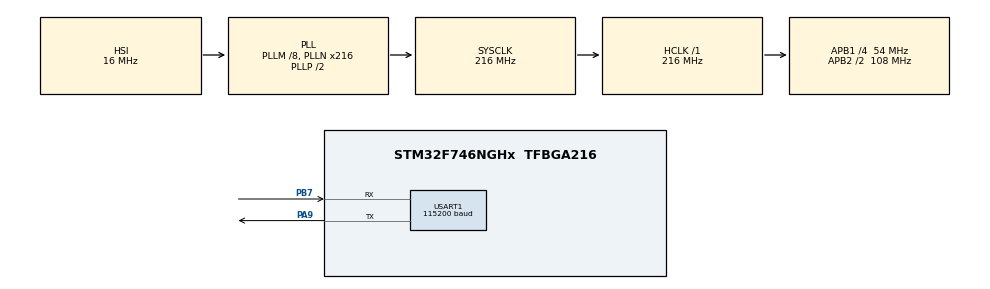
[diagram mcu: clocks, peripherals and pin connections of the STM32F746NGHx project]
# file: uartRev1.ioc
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CORTEX_M7.ART_ACCLERATOR_ENABLE=1
CORTEX_M7.CPU_DCache=Enabled
CORTEX_M7.CPU_ICache=Enabled
CORTEX_M7.PREFETCH_ENABLE=1
Mcu.Family=STM32F7
Mcu.Name=STM32F746NGHx
Mcu.Package=TFBGA216
NVIC.PriorityGroup=NVIC_PRIORITYGROUP_4
NVIC.RCC_IRQn=true\:0\:0\:false\:false\:true\:true\:false
PA13.Mode=Serial_Wire
PA13.Signal=SYS_JTMS-SWDIO
PA14.Mode=Serial_Wire
PA14.Signal=SYS_JTCK-SWCLK
PA9.Mode=Asynchronous
PA9.Signal=USART1_TX
PB7.Mode=Asynchronous
PB7.Signal=USART1_RX
ProjectManager.HeapSize=0x200
ProjectManager.StackSize=0x400
ProjectManager.TargetToolchain=MDK-ARM V5.32
RCC.AHBFreq_Value=216000000
RCC.APB1CLKDivider=RCC_HCLK_DIV4
RCC.APB1Freq_Value=54000000
RCC.APB1TimFreq_Value=108000000
RCC.APB2CLKDivider=RCC_HCLK_DIV2
RCC.APB2Freq_Value=108000000
RCC.APB2TimFreq_Value=216000000
RCC.CortexFreq_Value=216000000
RCC.HCLKFreq_Value=216000000
RCC.HSE_VALUE=25000000
RCC.HSI_VALUE=16000000
RCC.LSE_VALUE=32768
RCC.PLLM=8
RCC.PLLN=216
RCC.PLLSourceVirtual=RCC_PLLSOURCE_HSI
RCC.SYSCLKFreq_VALUE=216000000
RCC.SYSCLKSource=RCC_SYSCLKSOURCE_PLLCLK
RCC.USBFreq_Value=216000000
RCC.VCOOutputFreq_Value=432000000
USART1.BaudRate=115200
USART1.VirtualMode-Asynchronous=VM_ASYNC
board=STM32F746G-DISCO

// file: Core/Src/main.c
/* USER CODE BEGIN Header */
/**
  ******************************************************************************
  * @file           : main.c
  * @brief          : Main program body
  ******************************************************************************
  * @attention
  *
  * <h2><center>&copy; Copyright (c) 2021 STMicroelectronics.
  * All rights reserved.</center></h2>
  *
  * This software component is licensed by ST under BSD 3-Clause license,
  * the "License"; You may not use this file except in compliance with the
  * License. You may obtain a copy of the License at:
  *                        opensource.org/licenses/BSD-3-Clause
  *
  ******************************************************************************
  */
/* USER CODE END Header */
#include "main.h"

/* USER CODE BEGIN Includes */
#include "stdio.h"
#include "arm_nnfunctions.h"
#include "model.h"
#include "utils.h"
#include "inputs.h"

/* USER CODE END Includes */

/* USER CODE BEGIN PD */
int stdout_putchar (int ch);
/* USER CODE END PD */

UART_HandleTypeDef huart1;

void SystemClock_Config(void);
static void MX_GPIO_Init(void);
static void MX_USART1_UART_Init(void);

int main(void)
{

  /* Enable I-Cache---------------------------------------------------------*/
  SCB_EnableICache();

  /* Enable D-Cache---------------------------------------------------------*/
  SCB_EnableDCache();

  /* MCU Configuration--------------------------------------------------------*/

  /* Reset of all peripherals, Initializes the Flash interface and the Systick. */
  HAL_Init();

  /* Configure the system clock */
  SystemClock_Config();

  /* Initialize all configured peripherals */
  MX_GPIO_Init();
  MX_USART1_UART_Init();

  /* Infinite loop */
  /* USER CODE BEGIN WHILE */
  while (1)
  {
    q7_t buffer1[784] = INPUT_DATA;
    q7_t buffer2[120] = {0};
    mlp(buffer1, buffer2);

    int max_index = get_vector_max_index(buffer1, 10, 1);
    // printf("label: %d\r\n", max_index);

		HAL_Delay(100);
  }
  /* USER CODE END 3 */
}

void SystemClock_Config(void)
{
  RCC_OscInitTypeDef RCC_OscInitStruct = {0};
  RCC_ClkInitTypeDef RCC_ClkInitStruct = {0};
  RCC_PeriphCLKInitTypeDef PeriphClkInitStruct = {0};

  /** Configure the main internal regulator output voltage
  */
  __HAL_RCC_PWR_CLK_ENABLE();
  __HAL_PWR_VOLTAGESCALING_CONFIG(PWR_REGULATOR_VOLTAGE_SCALE1);
  /** Initializes the RCC Oscillators according to the specified parameters
  * in the RCC_OscInitTypeDef structure.
  */
  RCC_OscInitStruct.OscillatorType = RCC_OSCILLATORTYPE_HSI;
  RCC_OscInitStruct.HSIState = RCC_HSI_ON;
  RCC_OscInitStruct.HSICalibrationValue = RCC_HSICALIBRATION_DEFAULT;
  RCC_OscInitStruct.PLL.PLLState = RCC_PLL_ON;
  RCC_OscInitStruct.PLL.PLLSource = RCC_PLLSOURCE_HSI;
  RCC_OscInitStruct.PLL.PLLM = 8;
  RCC_OscInitStruct.PLL.PLLN = 216;
  RCC_OscInitStruct.PLL.PLLP = RCC_PLLP_DIV2;
  RCC_OscInitStruct.PLL.PLLQ = 2;
  if (HAL_RCC_OscConfig(&RCC_OscInitStruct) != HAL_OK)
  {
    Error_Handler();
  }
  /** Activate the Over-Drive mode
  */
  if (HAL_PWREx_EnableOverDrive() != HAL_OK)
  {
    Error_Handler();
  }
  /** Initializes the CPU, AHB and APB buses clocks
  */
  RCC_ClkInitStruct.ClockType = RCC_CLOCKTYPE_HCLK|RCC_CLOCKTYPE_SYSCLK
                              |RCC_CLOCKTYPE_PCLK1|RCC_CLOCKTYPE_PCLK2;
  RCC_ClkInitStruct.SYSCLKSource = RCC_SYSCLKSOURCE_PLLCLK;
  RCC_ClkInitStruct.AHBCLKDivider = RCC_SYSCLK_DIV1;
  RCC_ClkInitStruct.APB1CLKDivider = RCC_HCLK_DIV4;
  RCC_ClkInitStruct.APB2CLKDivider = RCC_HCLK_DIV2;

  if (HAL_RCC_ClockConfig(&RCC_ClkInitStruct, FLASH_LATENCY_7) != HAL_OK)
  {
    Error_Handler();
  }
  PeriphClkInitStruct.PeriphClockSelection = RCC_PERIPHCLK_USART1;
  PeriphClkInitStruct.Usart1ClockSelection = RCC_USART1CLKSOURCE_PCLK2;
  if (HAL_RCCEx_PeriphCLKConfig(&PeriphClkInitStruct) != HAL_OK)
  {
    Error_Handler();
  }
}

static void MX_USART1_UART_Init(void)
{

  huart1.Instance = USART1;
  huart1.Init.BaudRate = 115200;
  huart1.Init.WordLength = UART_WORDLENGTH_8B;
  huart1.Init.StopBits = UART_STOPBITS_1;
  huart1.Init.Parity = UART_PARITY_NONE;
  huart1.Init.Mode = UART_MODE_TX_RX;
  huart1.Init.HwFlowCtl = UART_HWCONTROL_NONE;
  huart1.Init.OverSampling = UART_OVERSAMPLING_16;
  huart1.Init.OneBitSampling = UART_ONE_BIT_SAMPLE_DISABLE;
  huart1.AdvancedInit.AdvFeatureInit = UART_ADVFEATURE_NO_INIT;
  if (HAL_UART_Init(&huart1) != HAL_OK)
  {
    Error_Handler();
  }

}

static void MX_GPIO_Init(void)
{

  /* GPIO Ports Clock Enable */
  __HAL_RCC_GPIOA_CLK_ENABLE();
  __HAL_RCC_GPIOB_CLK_ENABLE();

}

/* USER CODE BEGIN 4 */
int stdout_putchar(int ch)
{
    HAL_UART_Transmit(&huart1, (uint8_t *)&ch, 1, 0xFFFF);
    return ch;
}

/* USER CODE END 4 */

void Error_Handler(void)
{
  __disable_irq();
  while (1)
  {
  }
}

/************************ (C) COPYRIGHT STMicroelectronics *****END OF FILE****/
